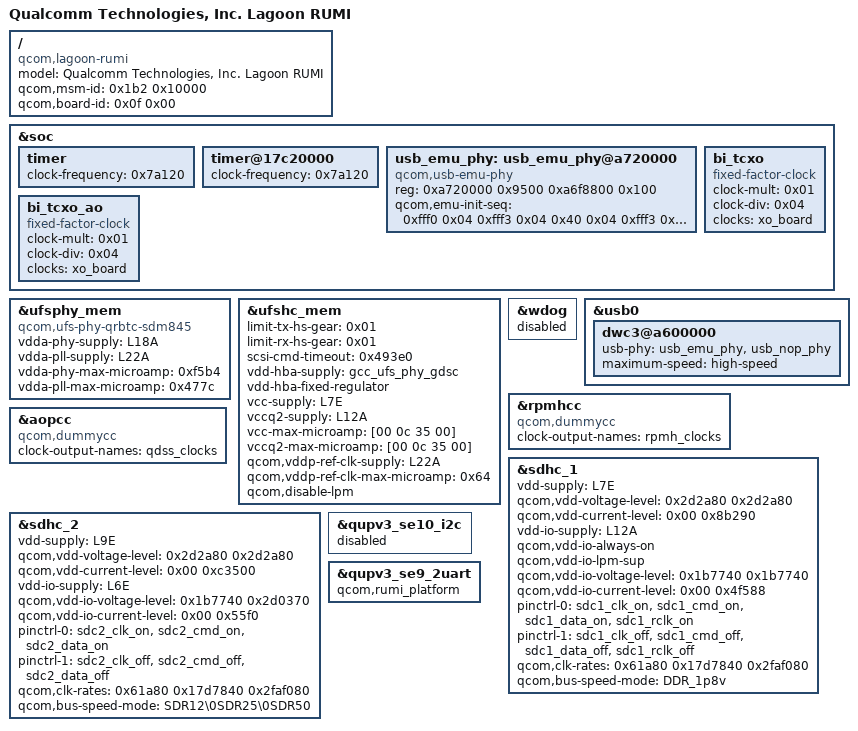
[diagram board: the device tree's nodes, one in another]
/dts-v1/;
/plugin/;

/ {
	model = "Qualcomm Technologies, Inc. Lagoon RUMI";
	compatible = "qcom,lagoon-rumi\0qcom,lagoon\0qcom,rumi";
	qcom,msm-id = <0x1b2 0x10000>;
	qcom,board-id = <0x0f 0x00>;

	fragment@0 {
		target = <&soc>;

		__overlay__ {

			timer {
				clock-frequency = <0x7a120>;
			};

			timer@17c20000 {
				clock-frequency = <0x7a120>;
			};

			usb_emu_phy: usb_emu_phy@a720000 {
				compatible = "qcom,usb-emu-phy";
				reg = <0xa720000 0x9500 0xa6f8800 0x100>;
				reg-names = "base\0qscratch_base";
				qcom,emu-init-seq = <0xfff0 0x04 0xfff3 0x04 0x40 0x04 0xfff3 0x04 0xfff0 0x04 0x100000 0x20 0x00 0x20 0x1a0 0x20 0x100000 0x3c 0x00 0x3c 0x10060 0x3c 0x00 0x04>;
			};

			bi_tcxo: bi_tcxo {
				compatible = "fixed-factor-clock";
				clock-mult = <0x01>;
				clock-div = <0x04>;
				clocks = <&xo_board>;
				#clock-cells = <0x00>;
			};

			bi_tcxo_ao: bi_tcxo_ao {
				compatible = "fixed-factor-clock";
				clock-mult = <0x01>;
				clock-div = <0x04>;
				clocks = <&xo_board>;
				#clock-cells = <0x00>;
			};
		};
	};

	fragment@1 {
		target = <&ufsphy_mem>;

		__overlay__ {
			compatible = "qcom,ufs-phy-qrbtc-sdm845";
			vdda-phy-supply = <&L18A>;
			vdda-pll-supply = <&L22A>;
			vdda-phy-max-microamp = <0xf5b4>;
			vdda-pll-max-microamp = <0x477c>;
			status = "ok";
		};
	};

	fragment@2 {
		target = <&ufshc_mem>;

		__overlay__ {
			limit-tx-hs-gear = <0x01>;
			limit-rx-hs-gear = <0x01>;
			scsi-cmd-timeout = <0x493e0>;
			vdd-hba-supply = <&gcc_ufs_phy_gdsc>;
			vdd-hba-fixed-regulator;
			vcc-supply = <&L7E>;
			vccq2-supply = <&L12A>;
			vcc-max-microamp = [00 0c 35 00];
			vccq2-max-microamp = [00 0c 35 00];
			qcom,vddp-ref-clk-supply = <&L22A>;
			qcom,vddp-ref-clk-max-microamp = <0x64>;
			qcom,disable-lpm;
			status = "ok";
		};
	};

	fragment@3 {
		target = <&wdog>;

		__overlay__ {
			status = "disabled";
		};
	};

	fragment@4 {
		target = <&usb0>;

		__overlay__ {

			dwc3@a600000 {
				usb-phy = <&usb_emu_phy &usb_nop_phy>;
				maximum-speed = "high-speed";
			};
		};
	};

	fragment@5 {
		target = <&rpmhcc>;

		__overlay__ {
			compatible = "qcom,dummycc";
			clock-output-names = "rpmh_clocks";
		};
	};

	fragment@6 {
		target = <&aopcc>;

		__overlay__ {
			compatible = "qcom,dummycc";
			clock-output-names = "qdss_clocks";
		};
	};

	fragment@7 {
		target = <&sdhc_1>;

		__overlay__ {
			vdd-supply = <&L7E>;
			qcom,vdd-voltage-level = <0x2d2a80 0x2d2a80>;
			qcom,vdd-current-level = <0x00 0x8b290>;
			vdd-io-supply = <&L12A>;
			qcom,vdd-io-always-on;
			qcom,vdd-io-lpm-sup;
			qcom,vdd-io-voltage-level = <0x1b7740 0x1b7740>;
			qcom,vdd-io-current-level = <0x00 0x4f588>;
			pinctrl-names = "active\0sleep";
			pinctrl-0 = <&sdc1_clk_on &sdc1_cmd_on &sdc1_data_on &sdc1_rclk_on>;
			pinctrl-1 = <&sdc1_clk_off &sdc1_cmd_off &sdc1_data_off &sdc1_rclk_off>;
			qcom,clk-rates = <0x61a80 0x17d7840 0x2faf080>;
			qcom,bus-speed-mode = "DDR_1p8v";
			status = "ok";
		};
	};

	fragment@8 {
		target = <&sdhc_2>;

		__overlay__ {
			vdd-supply = <&L9E>;
			qcom,vdd-voltage-level = <0x2d2a80 0x2d2a80>;
			qcom,vdd-current-level = <0x00 0xc3500>;
			vdd-io-supply = <&L6E>;
			qcom,vdd-io-voltage-level = <0x1b7740 0x2d0370>;
			qcom,vdd-io-current-level = <0x00 0x55f0>;
			pinctrl-names = "active\0sleep";
			pinctrl-0 = <&sdc2_clk_on &sdc2_cmd_on &sdc2_data_on>;
			pinctrl-1 = <&sdc2_clk_off &sdc2_cmd_off &sdc2_data_off>;
			qcom,clk-rates = <0x61a80 0x17d7840 0x2faf080>;
			qcom,bus-speed-mode = "SDR12\0SDR25\0SDR50";
			status = "ok";
		};
	};

	fragment@9 {
		target = <&qupv3_se10_i2c>;

		__overlay__ {
			status = "disabled";
		};
	};

	fragment@10 {
		target = <&qupv3_se9_2uart>;

		__overlay__ {
			qcom,rumi_platform;
		};
	};
};
